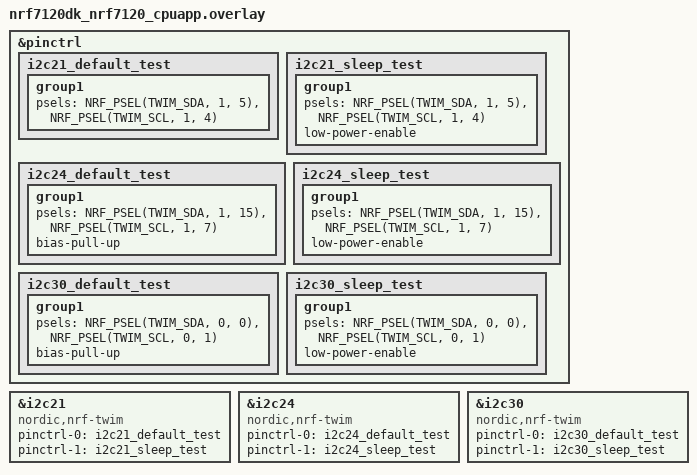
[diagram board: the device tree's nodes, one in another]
&pinctrl {
	i2c21_default_test: i2c21_default_test {
		group1 {
			psels = <NRF_PSEL(TWIM_SDA, 1, 5)>,
				<NRF_PSEL(TWIM_SCL, 1, 4)>;
		};
	};

	i2c21_sleep_test: i2c21_sleep_test {
		group1 {
			psels = <NRF_PSEL(TWIM_SDA, 1, 5)>,
				<NRF_PSEL(TWIM_SCL, 1, 4)>;
			low-power-enable;
		};
	};

	i2c24_default_test: i2c24_default_test {
		group1 {
			psels = <NRF_PSEL(TWIM_SDA, 1, 15)>,
				<NRF_PSEL(TWIM_SCL, 1, 7)>;
			bias-pull-up;
		};
	};

	i2c24_sleep_test: i2c24_sleep_test {
		group1 {
			psels = <NRF_PSEL(TWIM_SDA, 1, 15)>,
				<NRF_PSEL(TWIM_SCL, 1, 7)>;
			low-power-enable;
		};
	};

	i2c30_default_test: i2c30_default_test {
		group1 {
			psels = <NRF_PSEL(TWIM_SDA, 0, 0)>,
				<NRF_PSEL(TWIM_SCL, 0, 1)>;
			bias-pull-up;
		};
	};

	i2c30_sleep_test: i2c30_sleep_test {
		group1 {
			psels = <NRF_PSEL(TWIM_SDA, 0, 0)>,
				<NRF_PSEL(TWIM_SCL, 0, 1)>;
			low-power-enable;
		};
	};
};

&i2c21 {
	compatible = "nordic,nrf-twim";
	status = "okay";
	pinctrl-0 = <&i2c21_default_test>;
	pinctrl-1 = <&i2c21_sleep_test>;
	pinctrl-names = "default", "sleep";
};

&i2c24 {
	compatible = "nordic,nrf-twim";
	status = "okay";
	pinctrl-0 = <&i2c24_default_test>;
	pinctrl-1 = <&i2c24_sleep_test>;
	pinctrl-names = "default", "sleep";
};

&i2c30 {
	compatible = "nordic,nrf-twim";
	status = "okay";
	pinctrl-0 = <&i2c30_default_test>;
	pinctrl-1 = <&i2c30_sleep_test>;
	pinctrl-names = "default", "sleep";
};
